# PY32F002Bxx register map
Vendor: Puya; Series: PY32F0; File version: 1.0.0
CPU: CM0+ r0p1, little endian, no MPU, no FPU, 4 interrupt priority bits
Registers are 32-bit, read-write, reset 0x0 unless marked. A register's access mark holds for its fields unless they carry their own. Offsets are from the block's base; [hi:lo] are bit positions; {n}, {i} and the like mark numbered series; 'fields as' and 'values as' point back to an identical list.

## EXTI — External interrupt/event controller
Base 0x40021800
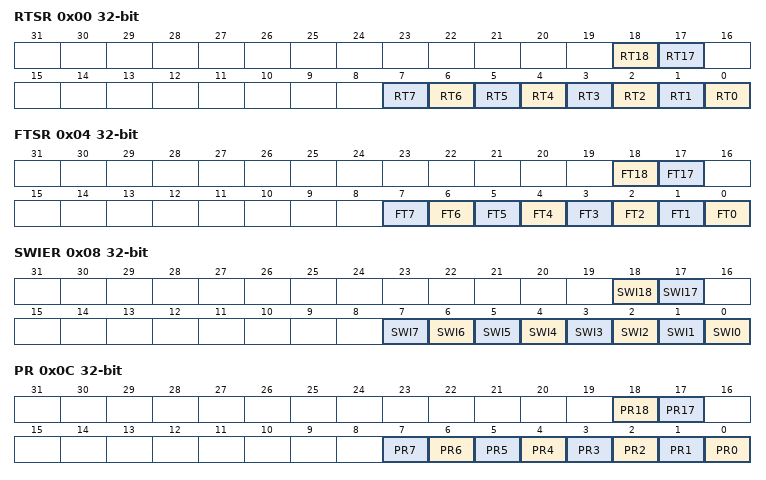
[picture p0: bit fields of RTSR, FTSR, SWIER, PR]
0x00 RTSR — EXTI rising trigger selection register
  [all] fields
    0=Disabled (Rising edge trigger is disabled); 1=Enabled (Rising edge trigger is enabled)
  [18] RT18 — Rising trigger event configuration bit of Configurable Event input
  [17] RT17 — Rising trigger event configuration bit of Configurable Event input
  [n] RT{n} (n=0..7) — Rising trigger event configuration bit of Configurable Event input
0x04 FTSR — EXTI falling trigger selection register
  [all] fields
    0=Disabled (Falling edge trigger is disabled); 1=Enabled (Falling edge trigger is enabled)
  [18] FT18 — Falling trigger event configuration bit of Configurable Event input
  [17] FT17 — Falling trigger event configuration bit of Configurable Event input
  [n] FT{n} (n=0..7) — Falling trigger event configuration bit of Configurable Event input
0x08 SWIER — EXTI software interrupt event register
  [all] fields
    on write: 1=Pend (Generates an interrupt request)
  [18] SWI18 — Rising trigger event configuration bit of Configurable Event input
  [17] SWI17 — Rising trigger event configuration bit of Configurable Event input
  [n] SWI{n} (n=0..7) — Rising trigger event configuration bit of Configurable Event input
0x0C PR — EXTI pending register
  [all] fields
    on read: 0=NotPending (No trigger request occurred); 1=Pending (Selected trigger request occurred) | on write: 1=Clears pending bit
  [18] PR18 write-1-clears — configurable event inputs x rising edge Pending bit.
  [17] PR17 write-1-clears — configurable event inputs x rising edge Pending bit.
  [n] PR{n} write-1-clears (n=0..7) — configurable event inputs x rising edge Pending bit.
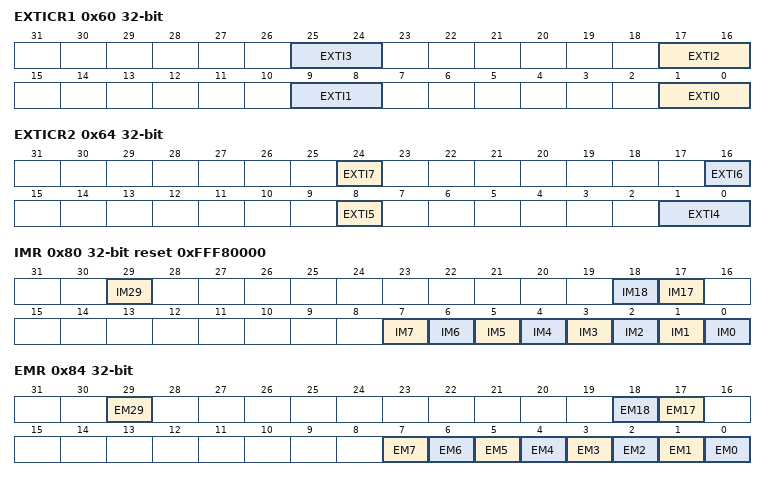
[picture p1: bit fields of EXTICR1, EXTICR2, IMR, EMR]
0x60 EXTICR1 — EXTI external interrupt selection register
  [all] fields
    0=PA (GPIO port A selected); 1=PB (GPIO port B selected); 2=PF (GPIO port F selected)
  [8n+1:8n] EXTI{n} (n=0..3) — GPIO port selection
0x64 EXTICR2 — EXTI external interrupt selection register
  [24] EXTI7 — GPIO port selection
    0=PA (GPIO port A selected); 1=PB (GPIO port B selected)
  [16] EXTI6 — GPIO port selection
    0=PA (GPIO port A selected); 1=PB (GPIO port B selected)
  [8] EXTI5 — GPIO port selection
    0=PA (GPIO port A selected); 1=PB (GPIO port B selected)
  [1:0] EXTI4 — GPIO port selection
    values as the fields of EXTICR1
0x80 IMR reset 0xFFF80000 — EXTI CPU wakeup with interrupt mask register
  [all] fields
    0=Masked (Interrupt request line is masked); 1=Unmasked (Interrupt request line is unmasked)
  [29] IM29 — CPU wakeup with interrupt mask on event input
  [18] IM18 — CPU wakeup with interrupt mask on event input
  [17] IM17 — CPU wakeup with interrupt mask on event input
  [n] IM{n} (n=0..7) — CPU wakeup with interrupt mask on event input
0x84 EMR — EXTI CPU wakeup with event mask register
  [all] fields
    values as the fields of IMR
  [29] EM29 — CPU wakeup with event mask on event input
  [18] EM18 — CPU wakeup with event mask on event input
  [17] EM17 — CPU wakeup with event mask on event input
  [n] EM{n} (n=0..7) — CPU wakeup with event mask on event input

## LPTIM1 — Low power timer
Base 0x40007C00
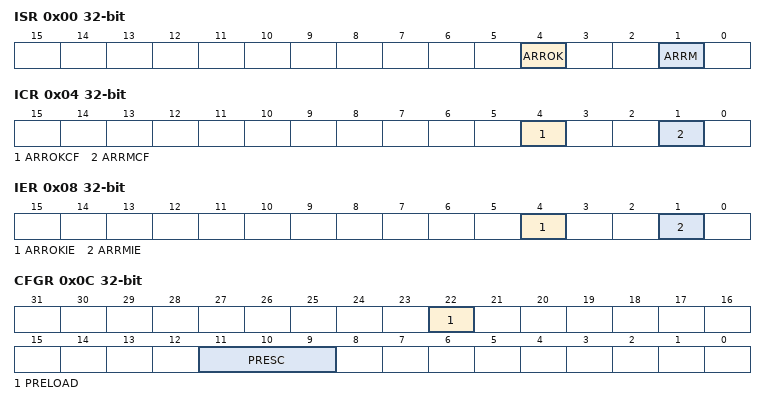
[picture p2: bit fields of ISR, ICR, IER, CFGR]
0x00 ISR ro — Interrupt and Status Register
  [4] ARROK — Autoreload match update OK
  [1] ARRM — Autoreload match
    1=Set (Autoreload match)
0x04 ICR wo — Interrupt Clear Register
  [4] ARROKCF — Autoreload match update OK Clear Flag
  [1] ARRMCF — Autoreload match Clear Flag
    1=Clear (Autoreload match Clear Flag)
0x08 IER — Interrupt Enable Register
  [4] ARROKIE — Autoreload match update OK Interrupt Enable
  [1] ARRMIE — Autoreload matchInterrupt Enable
    0=Disabled (ARRM interrupt disabled); 1=Enabled (ARRM interrupt enabled)
0x0C CFGR — Configuration Register
  [22] PRELOAD — Registers update mode
    0=Immediate (Registers are updated after each APB bus write access); 1=EndOfPeriod (Registers are updated at the end of the current LPTIM period)
  [11:9] PRESC — Clock prescaler
    0=Div1 (/1); 1=Div2 (/2); 2=Div4 (/4); 3=Div8 (/8); 4=Div16 (/16); 5=Div32 (/32); 6=Div64 (/64); 7=Div128 (/128)
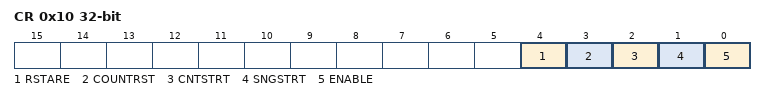
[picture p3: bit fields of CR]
0x10 CR — Control Register
  [4] RSTARE — Reset after read enable
    0=Disabled (CNT Register reads do not trigger reset); 1=Enabled (CNT Register reads trigger reset of LPTIM)
  [3] COUNTRST — Reset counter
  [2] CNTSTRT
  [1] SNGSTRT — LPTIM start in single mode
    on write: 1=Start (LPTIM start in Single mode)
  [0] ENABLE — LPTIM Enable
    0=Disabled (LPTIM is disabled); 1=Enabled (LPTIM is enabled)
0x18 ARR reset 0x1 — Autoreload Register
  [15:0] ARR — Auto reload value
0x1C CNT ro — Counter Register
  [15:0] CNT — Counter value
